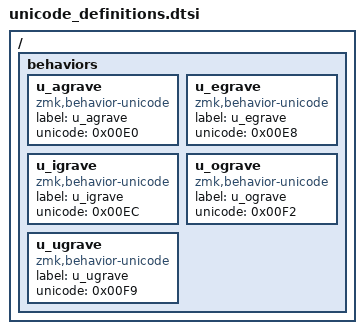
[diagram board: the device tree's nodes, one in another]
/ {
    behaviors {
        u_agrave: u_agrave {
            compatible = "zmk,behavior-unicode";
            label = "u_agrave";
            unicode = <0x00E0>;
        };

        u_egrave: u_egrave {
            compatible = "zmk,behavior-unicode";
            label = "u_egrave";
            unicode = <0x00E8>;
        };

        u_igrave: u_igrave {
            compatible = "zmk,behavior-unicode";
            label = "u_igrave";
            unicode = <0x00EC>;
        };

        u_ograve: u_ograve {
            compatible = "zmk,behavior-unicode";
            label = "u_ograve";
            unicode = <0x00F2>;
        };

        u_ugrave: u_ugrave {
            compatible = "zmk,behavior-unicode";
            label = "u_ugrave";
            unicode = <0x00F9>;
        };
    };
};

